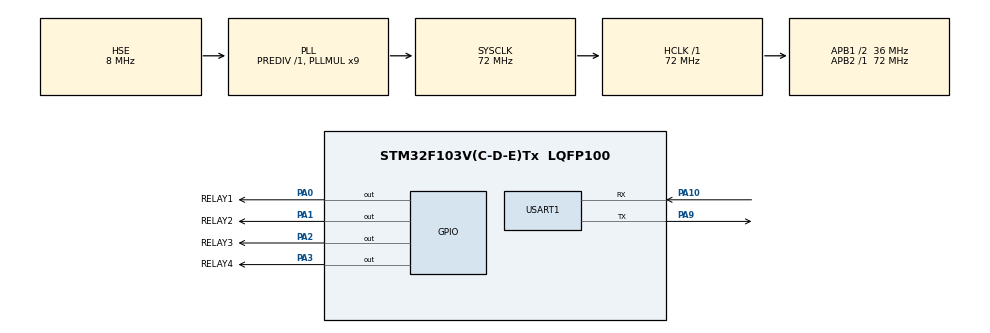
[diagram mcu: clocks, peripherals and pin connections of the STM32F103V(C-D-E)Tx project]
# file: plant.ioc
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FREERTOS.Tasks01=uartTask,0,128,startUartTask,Default,NULL,Dynamic,NULL,NULL;relayTask,0,128,startRelayTask,Default,NULL,Dynamic,NULL,NULL
Mcu.Family=STM32F1
Mcu.Name=STM32F103V(C-D-E)Tx
Mcu.Package=LQFP100
NVIC.PriorityGroup=NVIC_PRIORITYGROUP_4
NVIC.TIM1_UP_IRQn=true\:0\:0\:false\:false\:true\:false\:false\:true
NVIC.TimeBase=TIM1_UP_IRQn
NVIC.TimeBaseIP=TIM1
NVIC.USART1_IRQn=true\:5\:0\:false\:false\:true\:true\:true\:true
OSC_IN.Mode=HSE-External-Oscillator
OSC_IN.Signal=RCC_OSC_IN
OSC_OUT.Mode=HSE-External-Oscillator
OSC_OUT.Signal=RCC_OSC_OUT
PA0-WKUP.GPIO_Label=RELAY1
PA0-WKUP.Signal=GPIO_Output
PA1.GPIO_Label=RELAY2
PA1.Signal=GPIO_Output
PA10.Mode=Asynchronous
PA10.Signal=USART1_RX
PA13.Mode=JTAG_5_pins
PA13.Signal=SYS_JTMS-SWDIO
PA14.Mode=JTAG_5_pins
PA14.Signal=SYS_JTCK-SWCLK
PA15.Mode=JTAG_5_pins
PA15.Signal=SYS_JTDI
PA2.GPIO_Label=RELAY3
PA2.Signal=GPIO_Output
PA3.GPIO_Label=RELAY4
PA3.Signal=GPIO_Output
PA9.Mode=Asynchronous
PA9.Signal=USART1_TX
PB3.Mode=JTAG_5_pins
PB3.Signal=SYS_JTDO-TRACESWO
PB4.Mode=JTAG_5_pins
PB4.Signal=SYS_NJTRST
ProjectManager.HeapSize=0x200
ProjectManager.StackSize=0x400
ProjectManager.TargetToolchain=SW4STM32
RCC.AHBFreq_Value=72000000
RCC.APB1CLKDivider=RCC_HCLK_DIV2
RCC.APB1Freq_Value=36000000
RCC.APB1TimFreq_Value=72000000
RCC.APB2Freq_Value=72000000
RCC.APB2TimFreq_Value=72000000
RCC.HCLKFreq_Value=72000000
RCC.PLLMUL=RCC_PLL_MUL9
RCC.PLLSourceVirtual=RCC_PLLSOURCE_HSE
RCC.SYSCLKFreq_VALUE=72000000
RCC.SYSCLKSource=RCC_SYSCLKSOURCE_PLLCLK
RCC.USBFreq_Value=72000000
USART1.VirtualMode=VM_ASYNC
VP_FREERTOS_VS_CMSIS_V1.Mode=CMSIS_V1
VP_SYS_VS_tim1.Mode=TIM1
board=custom

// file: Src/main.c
/* USER CODE BEGIN Header */
/**
  ******************************************************************************
  * @file           : main.c
  * @brief          : Main program body
  ******************************************************************************
  * @attention
  *
  * <h2><center>&copy; Copyright (c) 2021 STMicroelectronics.
  * All rights reserved.</center></h2>
  *
  * This software component is licensed by ST under BSD 3-Clause license,
  * the "License"; You may not use this file except in compliance with the
  * License. You may obtain a copy of the License at:
  *                        opensource.org/licenses/BSD-3-Clause
  *
  ******************************************************************************
  */
/* USER CODE END Header */

#include "main.h"
#include "cmsis_os.h"
#include "usart.h"
#include "gpio.h"

void SystemClock_Config(void);
void MX_FREERTOS_Init(void);

int main(void)
{

  /* MCU Configuration--------------------------------------------------------*/

  /* Reset of all peripherals, Initializes the Flash interface and the Systick. */
  HAL_Init();

  /* Configure the system clock */
  SystemClock_Config();

  /* Initialize all configured peripherals */
  MX_GPIO_Init();
  MX_USART1_UART_Init();

  /* Call init function for freertos objects (in freertos.c) */
  MX_FREERTOS_Init();

  /* Start scheduler */
  osKernelStart();

  /* We should never get here as control is now taken by the scheduler */

  /* Infinite loop */
  while (1)
  {

  }
}

void SystemClock_Config(void)
{
  RCC_OscInitTypeDef RCC_OscInitStruct = {0};
  RCC_ClkInitTypeDef RCC_ClkInitStruct = {0};

  /** Initializes the CPU, AHB and APB busses clocks
  */
  RCC_OscInitStruct.OscillatorType = RCC_OSCILLATORTYPE_HSE;
  RCC_OscInitStruct.HSEState = RCC_HSE_ON;
  RCC_OscInitStruct.HSEPredivValue = RCC_HSE_PREDIV_DIV1;
  RCC_OscInitStruct.HSIState = RCC_HSI_ON;
  RCC_OscInitStruct.PLL.PLLState = RCC_PLL_ON;
  RCC_OscInitStruct.PLL.PLLSource = RCC_PLLSOURCE_HSE;
  RCC_OscInitStruct.PLL.PLLMUL = RCC_PLL_MUL9;
  if (HAL_RCC_OscConfig(&RCC_OscInitStruct) != HAL_OK)
  {
    Error_Handler();
  }
  /** Initializes the CPU, AHB and APB busses clocks
  */
  RCC_ClkInitStruct.ClockType = RCC_CLOCKTYPE_HCLK|RCC_CLOCKTYPE_SYSCLK
                              |RCC_CLOCKTYPE_PCLK1|RCC_CLOCKTYPE_PCLK2;
  RCC_ClkInitStruct.SYSCLKSource = RCC_SYSCLKSOURCE_PLLCLK;
  RCC_ClkInitStruct.AHBCLKDivider = RCC_SYSCLK_DIV1;
  RCC_ClkInitStruct.APB1CLKDivider = RCC_HCLK_DIV2;
  RCC_ClkInitStruct.APB2CLKDivider = RCC_HCLK_DIV1;

  if (HAL_RCC_ClockConfig(&RCC_ClkInitStruct, FLASH_LATENCY_2) != HAL_OK)
  {
    Error_Handler();
  }
}

void HAL_TIM_PeriodElapsedCallback(TIM_HandleTypeDef *htim)
{
  if (htim->Instance == TIM1) {
    HAL_IncTick();
  }
}

void Error_Handler(void)
{
}

/************************ (C) COPYRIGHT STMicroelectronics *****END OF FILE****/

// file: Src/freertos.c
/* USER CODE BEGIN Header */
/**
  ******************************************************************************
  * File Name          : freertos.c
  * Description        : Code for freertos applications
  ******************************************************************************
  * @attention
  *
  * <h2><center>&copy; Copyright (c) 2021 STMicroelectronics.
  * All rights reserved.</center></h2>
  *
  * This software component is licensed by ST under Ultimate Liberty license
  * SLA0044, the "License"; You may not use this file except in compliance with
  * the License. You may obtain a copy of the License at:
  *                             www.st.com/SLA0044
  *
  ******************************************************************************
  */
/* USER CODE END Header */

#include "FreeRTOS.h"
#include "task.h"
#include "main.h"
#include "cmsis_os.h"

/* USER CODE BEGIN Includes */
#include "usart.h"
/* USER CODE END Includes */

osThreadId uartTaskHandle;
osThreadId relayTaskHandle;

void startUartTask(void const * argument);
void startRelayTask(void const * argument);

void MX_FREERTOS_Init(void); /* (MISRA C 2004 rule 8.1) */

void MX_FREERTOS_Init(void) {

  /* Create the thread(s) */
  /* definition and creation of uartTask */
  osThreadDef(uartTask, startUartTask, osPriorityNormal, 0, 128);
  uartTaskHandle = osThreadCreate(osThread(uartTask), NULL);

  /* definition and creation of relayTask */
  osThreadDef(relayTask, startRelayTask, osPriorityNormal, 0, 128);
  relayTaskHandle = osThreadCreate(osThread(relayTask), NULL);

}

void startUartTask(void const * argument)
{

  /* USER CODE BEGIN startUartTask */
  /* Infinite loop */
    uartReceiver(&huart1);
  /* USER CODE END startUartTask */
}

void startRelayTask(void const * argument)
{
  for(;;)
  {
    osDelay(1);
  }
}

/************************ (C) COPYRIGHT STMicroelectronics *****END OF FILE****/
